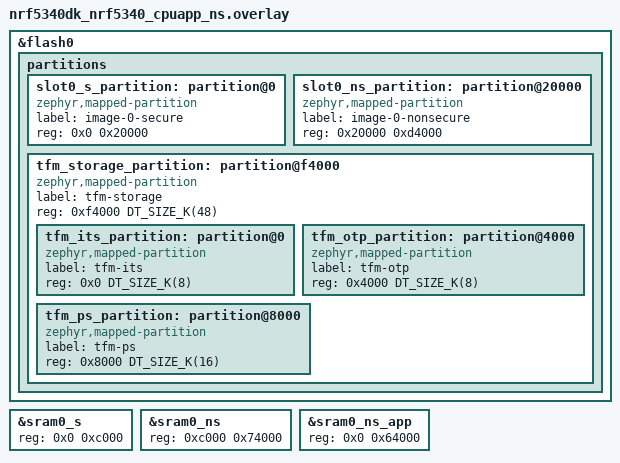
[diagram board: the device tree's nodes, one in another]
/*
 * Copyright (c) 2026 Nordic Semiconductor ASA
 *
 * SPDX-License-Identifier: LicenseRef-Nordic-5-Clause
 */

/delete-node/ &boot_partition;
/delete-node/ &slot0_partition;
/delete-node/ &slot1_partition;
/delete-node/ &tfm_its_partition;
/delete-node/ &tfm_otp_partition;
/delete-node/ &tfm_ps_partition;
/delete-node/ &storage_partition;

&flash0 {
	partitions {
		slot0_s_partition: partition@0 {
			compatible = "zephyr,mapped-partition";
			label = "image-0-secure";
			reg = <0x0 0x20000>;
		};

		slot0_ns_partition: partition@20000 {
			compatible = "zephyr,mapped-partition";
			label = "image-0-nonsecure";
			reg = <0x20000 0xd4000>;
		};

		tfm_storage_partition: partition@f4000 {
			compatible = "zephyr,mapped-partition";
			label = "tfm-storage";
			reg = <0xf4000 DT_SIZE_K(48)>;
			ranges = <0x0 0xf4000 DT_SIZE_K(48)>;
			#address-cells = <1>;
			#size-cells = <1>;

			tfm_its_partition: partition@0 {
				compatible = "zephyr,mapped-partition";
				label = "tfm-its";
				reg = <0x0 DT_SIZE_K(8)>;
			};

			tfm_otp_partition: partition@4000 {
				compatible = "zephyr,mapped-partition";
				label = "tfm-otp";
				reg = <0x4000 DT_SIZE_K(8)>;
			};

			tfm_ps_partition: partition@8000 {
				compatible = "zephyr,mapped-partition";
				label = "tfm-ps";
				reg = <0x8000 DT_SIZE_K(16)>;
			};
		};
	};
};

/*
 * TrustZone SRAM split from devicetree (region_defs.h for TF-M). The secure image uses
 * 48 KiB (0xc000) at the base of cpuapp SRAM (&sram0_s); NS RAM begins at 0x20000000 + 0xc000.
 * &sram0_ns spans 0x74000 bytes; &sram0_ns_app is 0x64000 because the top 0x10000 (64 KiB)
 * within that NS window is sram0_shared for application/network-core IPC
 * (nrf5340_shared_sram_partition.dtsi), i.e. 0x64000 + 0x10000 == 0x74000.
 */
&sram0_s {
	reg = <0x0 0xc000>;
};

&sram0_ns {
	reg = <0xc000 0x74000>;
	ranges = <0x0 0xc000 0x74000>;
};

&sram0_ns_app {
	reg = <0x0 0x64000>;
};
